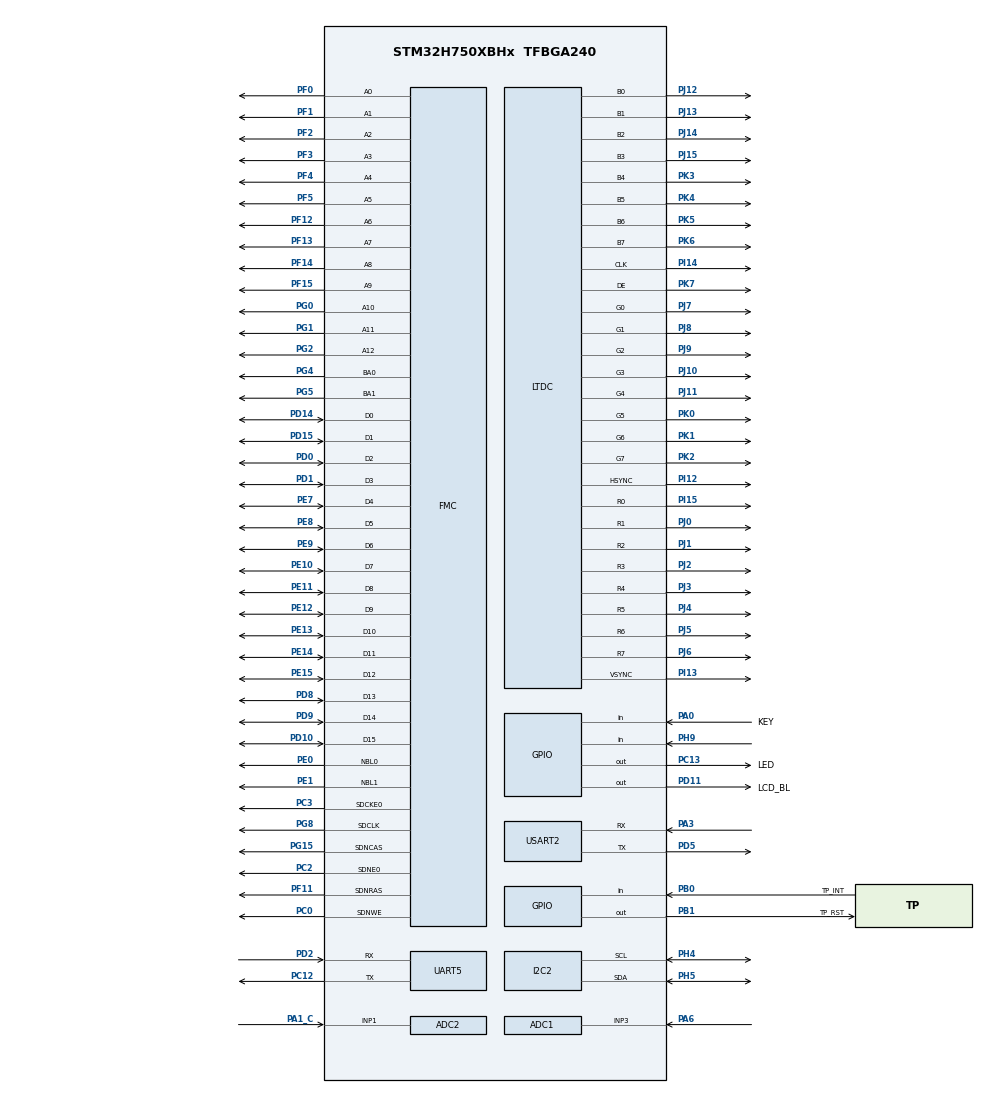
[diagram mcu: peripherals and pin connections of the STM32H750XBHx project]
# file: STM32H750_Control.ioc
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ADC1.Channel-0\#ChannelRegularConversion=ADC_CHANNEL_3
ADC1.NbrOfConversionFlag=1
ADC1.OffsetNumber-0\#ChannelRegularConversion=ADC_OFFSET_NONE
ADC1.OffsetSignedSaturation-0\#ChannelRegularConversion=DISABLE
ADC1.Rank-0\#ChannelRegularConversion=1
ADC1.SamplingTime-0\#ChannelRegularConversion=ADC_SAMPLETIME_1CYCLE_5
ADC1.master=1
ADC2.Channel-1\#ChannelRegularConversion=ADC_CHANNEL_1
ADC2.NbrOfConversionFlag=1
ADC2.OffsetNumber-1\#ChannelRegularConversion=ADC_OFFSET_NONE
ADC2.OffsetSignedSaturation-1\#ChannelRegularConversion=DISABLE
ADC2.Rank-1\#ChannelRegularConversion=1
ADC2.SamplingTime-1\#ChannelRegularConversion=ADC_SAMPLETIME_1CYCLE_5
DMA2D.ColorMode=DMA2D_OUTPUT_RGB888
FMC.CASLatency1=FMC_SDRAM_CAS_LATENCY_3
FMC.ColumnBitsNumber1=FMC_SDRAM_COLUMN_BITS_NUM_9
FMC.ExitSelfRefreshDelay1=7
FMC.LoadToActiveDelay1=2
FMC.RCDDelay1=2
FMC.RPDelay1=2
FMC.ReadPipeDelay1=FMC_SDRAM_RPIPE_DELAY_1
FMC.RowCycleDelay1=7
FMC.SDClockPeriod1=FMC_SDRAM_CLOCK_PERIOD_2
FMC.SelfRefreshTime1=4
FMC.WriteRecoveryTime1=3
FREERTOS.Tasks01=defaultTask,0,2048,StartDefaultTask,Default,NULL,Dynamic,NULL,NULL
I2C2.Timing=0x307075B1
LTDC.ActiveW=800
LTDC.Alpha_L0=255
LTDC.FBStartAdress_L0=0
LTDC.HBP=46
LTDC.HFP=40
LTDC.HSync=1
LTDC.ImageHeight_L0=480
LTDC.ImageWidth_L0=800
LTDC.Layers=0
LTDC.PixelFormat_L0=LTDC_PIXEL_FORMAT_RGB888
LTDC.VBP=23
LTDC.VFP=10
LTDC.VSync=2
LTDC.WindowX1_L0=800
LTDC.WindowY1_L0=480
Mcu.Family=STM32H7
Mcu.Name=STM32H750XBHx
Mcu.Package=TFBGA240
NVIC.DMA2D_IRQn=true\:5\:0\:false\:false\:true\:true\:true\:true
NVIC.FMC_IRQn=true\:5\:0\:false\:false\:true\:true\:true\:true
NVIC.LTDC_IRQn=true\:5\:0\:false\:false\:true\:true\:true\:true
NVIC.PriorityGroup=NVIC_PRIORITYGROUP_4
NVIC.TIM7_IRQn=true\:0\:0\:false\:false\:true\:false\:false\:true
NVIC.TimeBase=TIM7_IRQn
NVIC.TimeBaseIP=TIM7
PA0.GPIO_Label=KEY
PA0.Signal=GPIO_Input
PA1_C.Signal=ADCx_INP1
PA3.Mode=Asynchronous
PA3.Signal=USART2_RX
PA6.Signal=ADCx_INP3
PA7.Signal=ADCx_INN3
PB0.GPIO_Label=TP_INT
PB0.Signal=GPIO_Input
PB1.GPIO_Label=TP_RST
PB1.GPIO_PuPd=GPIO_PULLUP
PB1.PinState=GPIO_PIN_SET
PB1.Signal=GPIO_Output
PC0.Signal=FMC_SDNWE
PC12.Mode=Asynchronous
PC12.Signal=UART5_TX
PC13.GPIO_Label=LED
PC13.Signal=GPIO_Output
PC2.Mode=SdramChipSelect1_1
PC2.Signal=FMC_SDNE0
PC3.Mode=SdramChipSelect1_1
PC3.Signal=FMC_SDCKE0
PD0.Signal=FMC_D2_DA2
PD1.Signal=FMC_D3_DA3
PD10.Signal=FMC_D15_DA15
PD11.GPIO_Label=LCD_BL
PD11.GPIO_PuPd=GPIO_PULLUP
PD11.PinState=GPIO_PIN_SET
PD11.Signal=GPIO_Output
PD14.Signal=FMC_D0_DA0
PD15.Signal=FMC_D1_DA1
PD2.Mode=Asynchronous
PD2.Signal=UART5_RX
PD5.Mode=Asynchronous
PD5.Signal=USART2_TX
PD8.Signal=FMC_D13_DA13
PD9.Signal=FMC_D14_DA14
PE0.Signal=FMC_NBL0
PE1.Signal=FMC_NBL1
PE10.Signal=FMC_D7_DA7
PE11.Signal=FMC_D8_DA8
PE12.Signal=FMC_D9_DA9
PE13.Signal=FMC_D10_DA10
PE14.Signal=FMC_D11_DA11
PE15.Signal=FMC_D12_DA12
PE7.Signal=FMC_D4_DA4
PE8.Signal=FMC_D5_DA5
PE9.Signal=FMC_D6_DA6
PF0.Signal=FMC_A0
PF1.Signal=FMC_A1
PF11.Signal=FMC_SDNRAS
PF12.Signal=FMC_A6
PF13.Signal=FMC_A7
PF14.Signal=FMC_A8
PF15.Signal=FMC_A9
PF2.Signal=FMC_A2
PF3.Signal=FMC_A3
PF4.Signal=FMC_A4
PF5.Signal=FMC_A5
PG0.Signal=FMC_A10
PG1.Signal=FMC_A11
PG15.Signal=FMC_SDNCAS
PG2.Signal=FMC_A12
PG4.Signal=FMC_A14_BA0
PG5.Signal=FMC_A15_BA1
PG8.Signal=FMC_SDCLK
PH0-OSC_IN\ (PH0).Mode=HSE-External-Oscillator
PH0-OSC_IN\ (PH0).Signal=RCC_OSC_IN
PH1-OSC_OUT\ (PH1).Mode=HSE-External-Oscillator
PH1-OSC_OUT\ (PH1).Signal=RCC_OSC_OUT
PH4.Mode=I2C
PH4.Signal=I2C2_SCL
PH5.Mode=I2C
PH5.Signal=I2C2_SDA
PH9.GPIO_PuPd=GPIO_PULLDOWN
PH9.Signal=GPIO_Input
PI12.Mode=RGB888
PI12.Signal=LTDC_HSYNC
PI13.Mode=RGB888
PI13.Signal=LTDC_VSYNC
PI14.Mode=RGB888
PI14.Signal=LTDC_CLK
PI15.Mode=RGB888
PI15.Signal=LTDC_R0
PJ0.Mode=RGB888
PJ0.Signal=LTDC_R1
PJ1.Mode=RGB888
PJ1.Signal=LTDC_R2
PJ10.Mode=RGB888
PJ10.Signal=LTDC_G3
PJ11.Mode=RGB888
PJ11.Signal=LTDC_G4
PJ12.Mode=RGB888
PJ12.Signal=LTDC_B0
PJ13.Mode=RGB888
PJ13.Signal=LTDC_B1
PJ14.Mode=RGB888
PJ14.Signal=LTDC_B2
PJ15.Mode=RGB888
PJ15.Signal=LTDC_B3
PJ2.Mode=RGB888
PJ2.Signal=LTDC_R3
PJ3.Mode=RGB888
PJ3.Signal=LTDC_R4
PJ4.Mode=RGB888
PJ4.Signal=LTDC_R5
PJ5.Mode=RGB888
PJ5.Signal=LTDC_R6
PJ6.Mode=RGB888
PJ6.Signal=LTDC_R7
PJ7.Mode=RGB888
PJ7.Signal=LTDC_G0
PJ8.Mode=RGB888
PJ8.Signal=LTDC_G1
PJ9.Mode=RGB888
PJ9.Signal=LTDC_G2
PK0.Mode=RGB888
PK0.Signal=LTDC_G5
PK1.Mode=RGB888
PK1.Signal=LTDC_G6
PK2.Mode=RGB888
PK2.Signal=LTDC_G7
PK3.Mode=RGB888
PK3.Signal=LTDC_B4
PK4.Mode=RGB888
PK4.Signal=LTDC_B5
PK5.Mode=RGB888
PK5.Signal=LTDC_B6
PK6.Mode=RGB888
PK6.Signal=LTDC_B7
PK7.Mode=RGB888
PK7.Signal=LTDC_DE
ProjectManager.HeapSize=0x200
ProjectManager.StackSize=0x400
ProjectManager.TargetToolchain=MDK-ARM V5.27
RCC.ADCFreq_Value=75000000
RCC.APB1Freq_Value=120000000
RCC.APB2Freq_Value=120000000
RCC.APB3Freq_Value=120000000
RCC.APB4Freq_Value=120000000
RCC.CortexFreq_Value=480000000
RCC.D1PPRE=RCC_APB3_DIV2
RCC.D2PPRE1=RCC_APB1_DIV2
RCC.D2PPRE2=RCC_APB2_DIV2
RCC.D3PPRE=RCC_APB4_DIV2
RCC.DIVM1=5
RCC.DIVM2=2
RCC.DIVM3=3
RCC.DIVN1=192
RCC.DIVN2=12
RCC.DIVN3=51
RCC.DIVR3=25
RCC.HCLKFreq_Value=240000000
RCC.HPRE=RCC_HCLK_DIV2
RCC.HSE_VALUE=25000000
RCC.PLL3FRACN=0
RCC.PLLFRACN=0
RCC.PLLSourceVirtual=RCC_PLLSOURCE_HSE
RCC.SYSCLKFreq_VALUE=480000000
RCC.SYSCLKSource=RCC_SYSCLKSOURCE_PLLCLK
RCC.USBFreq_Value=480000000
SH.ADCx_INN3.0=ADC2_INN3
SH.ADCx_INP1.0=ADC2_INP1,IN1-Single-Ended
SH.ADCx_INP3.0=ADC1_INP3,IN3-Single-Ended
SH.FMC_A0.0=FMC_A0,13b-sda1
SH.FMC_A1.0=FMC_A1,13b-sda1
SH.FMC_A10.0=FMC_A10,13b-sda1
SH.FMC_A11.0=FMC_A11,13b-sda1
SH.FMC_A12.0=FMC_A12,13b-sda1
SH.FMC_A14_BA0.0=FMC_BA0,FourSdramBanks1
SH.FMC_A15_BA1.0=FMC_BA1,FourSdramBanks1
SH.FMC_A2.0=FMC_A2,13b-sda1
SH.FMC_A3.0=FMC_A3,13b-sda1
SH.FMC_A4.0=FMC_A4,13b-sda1
SH.FMC_A5.0=FMC_A5,13b-sda1
SH.FMC_A6.0=FMC_A6,13b-sda1
SH.FMC_A7.0=FMC_A7,13b-sda1
SH.FMC_A8.0=FMC_A8,13b-sda1
SH.FMC_A9.0=FMC_A9,13b-sda1
SH.FMC_D0_DA0.0=FMC_D0,sd-16b-d1
SH.FMC_D10_DA10.0=FMC_D10,sd-16b-d1
SH.FMC_D11_DA11.0=FMC_D11,sd-16b-d1
SH.FMC_D12_DA12.0=FMC_D12,sd-16b-d1
SH.FMC_D13_DA13.0=FMC_D13,sd-16b-d1
SH.FMC_D14_DA14.0=FMC_D14,sd-16b-d1
SH.FMC_D15_DA15.0=FMC_D15,sd-16b-d1
SH.FMC_D1_DA1.0=FMC_D1,sd-16b-d1
SH.FMC_D2_DA2.0=FMC_D2,sd-16b-d1
SH.FMC_D3_DA3.0=FMC_D3,sd-16b-d1
SH.FMC_D4_DA4.0=FMC_D4,sd-16b-d1
SH.FMC_D5_DA5.0=FMC_D5,sd-16b-d1
SH.FMC_D6_DA6.0=FMC_D6,sd-16b-d1
SH.FMC_D7_DA7.0=FMC_D7,sd-16b-d1
SH.FMC_D8_DA8.0=FMC_D8,sd-16b-d1
SH.FMC_D9_DA9.0=FMC_D9,sd-16b-d1
SH.FMC_NBL0.0=FMC_NBL0,Sd2ByteEnable1
SH.FMC_NBL1.0=FMC_NBL1,Sd2ByteEnable1
SH.FMC_SDCLK.0=FMC_SDCLK,13b-sda1
SH.FMC_SDNCAS.0=FMC_SDNCAS,13b-sda1
SH.FMC_SDNRAS.0=FMC_SDNRAS,13b-sda1
SH.FMC_SDNWE.0=FMC_SDNWE,13b-sda1
STMicroelectronics.X-CUBE-TOUCHGFX.4.17.0.ApplicationCcGraphicsJjApplication=TouchGFXOoGenerator
STMicroelectronics.X-CUBE-TOUCHGFX.4.17.0.tgfx_address1=0xC0000000
STMicroelectronics.X-CUBE-TOUCHGFX.4.17.0.tgfx_address2=0xC0119400
STMicroelectronics.X-CUBE-TOUCHGFX.4.17.0.tgfx_buffering_strategy=Double
STMicroelectronics.X-CUBE-TOUCHGFX.4.17.0.tgfx_display_interface=disp_ltdc
STMicroelectronics.X-CUBE-TOUCHGFX.4.17.0.tgfx_hardware_accelerator=dma_2d
STMicroelectronics.X-CUBE-TOUCHGFX.4.17.0.tgfx_location=By Address
STMicroelectronics.X-CUBE-TOUCHGFX.4.17.0.tgfx_vsync=vsync_ltdc
USART2.VirtualMode-Asynchronous=VM_ASYNC
VP_CRC_VS_CRC.Mode=CRC_Activate
VP_DMA2D_VS_DMA2D.Mode=DMA2D_Activate
VP_FREERTOS_VS_CMSIS_V1.Mode=CMSIS_V1
VP_STMicroelectronics.X-CUBE-TOUCHGFX_VS_GraphicsJjApplication_4.17.0.Mode=GraphicsJjApplication
VP_SYS_VS_tim7.Mode=TIM7
board=custom

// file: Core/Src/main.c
/* USER CODE BEGIN Header */
/**
  ******************************************************************************
  * @file           : main.c
  * @brief          : Main program body
  ******************************************************************************
  * @attention
  *
  * <h2><center>&copy; Copyright (c) 2020 STMicroelectronics.
  * All rights reserved.</center></h2>
  *
  * This software component is licensed by ST under Ultimate Liberty license
  * SLA0044, the "License"; You may not use this file except in compliance with
  * the License. You may obtain a copy of the License at:
  *                             www.st.com/SLA0044
  *
  ******************************************************************************
  */
/* USER CODE END Header */
#include "main.h"
#include "cmsis_os.h"
#include "app_touchgfx.h"

/* USER CODE BEGIN Includes */
#include "bsp_sdram.h"
#include "stdio.h"
/* USER CODE END Includes */

ADC_HandleTypeDef hadc1;
ADC_HandleTypeDef hadc2;

CRC_HandleTypeDef hcrc;

DMA2D_HandleTypeDef hdma2d;

I2C_HandleTypeDef hi2c2;

LTDC_HandleTypeDef hltdc;

UART_HandleTypeDef huart5;
UART_HandleTypeDef huart2;

SDRAM_HandleTypeDef hsdram1;

osThreadId defaultTaskHandle;

void SystemClock_Config(void);
static void MX_GPIO_Init(void);
static void MX_DMA2D_Init(void);
static void MX_FMC_Init(void);
static void MX_I2C2_Init(void);
static void MX_LTDC_Init(void);
static void MX_CRC_Init(void);
static void MX_UART5_Init(void);
static void MX_USART2_UART_Init(void);
static void MX_ADC2_Init(void);
static void MX_ADC1_Init(void);
void StartDefaultTask(void const * argument);

/* USER CODE BEGIN PFP */
int32_t adc_value;
int32_t i, j;
int32_t filter_temp, filter_sum = 0;
const int FILTER_N = 20;
int32_t filter_buf[FILTER_N];
/* USER CODE END PFP */

/* USER CODE BEGIN 0 */
#ifdef __GNUC__
#define PUTCHAR_PROTOTYPE int __io_putchar(int ch)
#else
#define PUTCHAR_PROTOTYPE int fputc(int ch, FILE *f)
#endif
PUTCHAR_PROTOTYPE
{
    HAL_UART_Transmit(&huart2 , (uint8_t *)&ch, 1, 0xFFFF);
    return ch;
}
/* USER CODE END 0 */

int main(void)
{

  /* MCU Configuration--------------------------------------------------------*/

  /* Reset of all peripherals, Initializes the Flash interface and the Systick. */
  HAL_Init();

  /* Configure the system clock */
  SystemClock_Config();

  /* Initialize all configured peripherals */
  MX_GPIO_Init();
  MX_DMA2D_Init();
  MX_FMC_Init();
  MX_I2C2_Init();
  MX_LTDC_Init();
  MX_CRC_Init();
  MX_UART5_Init();
  MX_USART2_UART_Init();
  MX_ADC2_Init();
  MX_ADC1_Init();
  MX_TouchGFX_Init();
  /* USER CODE BEGIN 2 */
	SDRAM_Init();
  /* USER CODE END 2 */

  /* Create the thread(s) */
  /* definition and creation of defaultTask */
  osThreadDef(defaultTask, StartDefaultTask, osPriorityNormal, 0, 2048);
  defaultTaskHandle = osThreadCreate(osThread(defaultTask), NULL);

  /* Start scheduler */
  osKernelStart();

  /* We should never get here as control is now taken by the scheduler */
  /* Infinite loop */
  /* USER CODE BEGIN WHILE */
  while (1)
  {	/*
		HAL_ADC_Start(&hadc2);
		HAL_ADC_PollForConversion(&hadc2,10);
		adc_value = HAL_ADC_GetValue(&hadc2);
		printf("ADC1_IN1 ADC value: %d\r\n",adc_value);
		adc_value = adc_value*(3.3/4096);
		printf("ADC1_IN1 VOL value: %.2fV\r\n",(double)adc_value);

		HAL_GPIO_TogglePin(GPIOA,GPIO_PIN_1);
		HAL_Delay(10);
		*/

    /* USER CODE END WHILE */

  }
}

void SystemClock_Config(void)
{
  RCC_OscInitTypeDef RCC_OscInitStruct = {0};
  RCC_ClkInitTypeDef RCC_ClkInitStruct = {0};
  RCC_PeriphCLKInitTypeDef PeriphClkInitStruct = {0};

  /** Supply configuration update enable
  */
  HAL_PWREx_ConfigSupply(PWR_LDO_SUPPLY);
  /** Configure the main internal regulator output voltage
  */
  __HAL_PWR_VOLTAGESCALING_CONFIG(PWR_REGULATOR_VOLTAGE_SCALE0);

  while(!__HAL_PWR_GET_FLAG(PWR_FLAG_VOSRDY)) {}
  /** Macro to configure the PLL clock source
  */
  __HAL_RCC_PLL_PLLSOURCE_CONFIG(RCC_PLLSOURCE_HSE);
  /** Initializes the RCC Oscillators according to the specified parameters
  * in the RCC_OscInitTypeDef structure.
  */
  RCC_OscInitStruct.OscillatorType = RCC_OSCILLATORTYPE_HSE;
  RCC_OscInitStruct.HSEState = RCC_HSE_ON;
  RCC_OscInitStruct.PLL.PLLState = RCC_PLL_ON;
  RCC_OscInitStruct.PLL.PLLSource = RCC_PLLSOURCE_HSE;
  RCC_OscInitStruct.PLL.PLLM = 5;
  RCC_OscInitStruct.PLL.PLLN = 192;
  RCC_OscInitStruct.PLL.PLLP = 2;
  RCC_OscInitStruct.PLL.PLLQ = 2;
  RCC_OscInitStruct.PLL.PLLR = 2;
  RCC_OscInitStruct.PLL.PLLRGE = RCC_PLL1VCIRANGE_2;
  RCC_OscInitStruct.PLL.PLLVCOSEL = RCC_PLL1VCOWIDE;
  RCC_OscInitStruct.PLL.PLLFRACN = 0;
  if (HAL_RCC_OscConfig(&RCC_OscInitStruct) != HAL_OK)
  {
    Error_Handler();
  }
  /** Initializes the CPU, AHB and APB buses clocks
  */
  RCC_ClkInitStruct.ClockType = RCC_CLOCKTYPE_HCLK|RCC_CLOCKTYPE_SYSCLK
                              |RCC_CLOCKTYPE_PCLK1|RCC_CLOCKTYPE_PCLK2
                              |RCC_CLOCKTYPE_D3PCLK1|RCC_CLOCKTYPE_D1PCLK1;
  RCC_ClkInitStruct.SYSCLKSource = RCC_SYSCLKSOURCE_PLLCLK;
  RCC_ClkInitStruct.SYSCLKDivider = RCC_SYSCLK_DIV1;
  RCC_ClkInitStruct.AHBCLKDivider = RCC_HCLK_DIV2;
  RCC_ClkInitStruct.APB3CLKDivider = RCC_APB3_DIV2;
  RCC_ClkInitStruct.APB1CLKDivider = RCC_APB1_DIV2;
  RCC_ClkInitStruct.APB2CLKDivider = RCC_APB2_DIV2;
  RCC_ClkInitStruct.APB4CLKDivider = RCC_APB4_DIV2;

  if (HAL_RCC_ClockConfig(&RCC_ClkInitStruct, FLASH_LATENCY_4) != HAL_OK)
  {
    Error_Handler();
  }
  PeriphClkInitStruct.PeriphClockSelection = RCC_PERIPHCLK_LTDC|RCC_PERIPHCLK_USART2
                              |RCC_PERIPHCLK_UART5|RCC_PERIPHCLK_I2C2
                              |RCC_PERIPHCLK_ADC|RCC_PERIPHCLK_FMC;
  PeriphClkInitStruct.PLL2.PLL2M = 2;
  PeriphClkInitStruct.PLL2.PLL2N = 12;
  PeriphClkInitStruct.PLL2.PLL2P = 2;
  PeriphClkInitStruct.PLL2.PLL2Q = 2;
  PeriphClkInitStruct.PLL2.PLL2R = 2;
  PeriphClkInitStruct.PLL2.PLL2RGE = RCC_PLL2VCIRANGE_3;
  PeriphClkInitStruct.PLL2.PLL2VCOSEL = RCC_PLL2VCOMEDIUM;
  PeriphClkInitStruct.PLL2.PLL2FRACN = 0;
  PeriphClkInitStruct.PLL3.PLL3M = 3;
  PeriphClkInitStruct.PLL3.PLL3N = 51;
  PeriphClkInitStruct.PLL3.PLL3P = 2;
  PeriphClkInitStruct.PLL3.PLL3Q = 2;
  PeriphClkInitStruct.PLL3.PLL3R = 25;
  PeriphClkInitStruct.PLL3.PLL3RGE = RCC_PLL3VCIRANGE_3;
  PeriphClkInitStruct.PLL3.PLL3VCOSEL = RCC_PLL3VCOWIDE;
  PeriphClkInitStruct.PLL3.PLL3FRACN = 0;
  PeriphClkInitStruct.FmcClockSelection = RCC_FMCCLKSOURCE_D1HCLK;
  PeriphClkInitStruct.Usart234578ClockSelection = RCC_USART234578CLKSOURCE_D2PCLK1;
  PeriphClkInitStruct.I2c123ClockSelection = RCC_I2C123CLKSOURCE_D2PCLK1;
  PeriphClkInitStruct.AdcClockSelection = RCC_ADCCLKSOURCE_PLL2;
  if (HAL_RCCEx_PeriphCLKConfig(&PeriphClkInitStruct) != HAL_OK)
  {
    Error_Handler();
  }
}

static void MX_ADC1_Init(void)
{

  ADC_MultiModeTypeDef multimode = {0};
  ADC_ChannelConfTypeDef sConfig = {0};

  /** Common config
  */
  hadc1.Instance = ADC1;
  hadc1.Init.ClockPrescaler = ADC_CLOCK_ASYNC_DIV1;
  hadc1.Init.Resolution = ADC_RESOLUTION_16B;
  hadc1.Init.ScanConvMode = ADC_SCAN_DISABLE;
  hadc1.Init.EOCSelection = ADC_EOC_SINGLE_CONV;
  hadc1.Init.LowPowerAutoWait = DISABLE;
  hadc1.Init.ContinuousConvMode = DISABLE;
  hadc1.Init.NbrOfConversion = 1;
  hadc1.Init.DiscontinuousConvMode = DISABLE;
  hadc1.Init.ExternalTrigConv = ADC_SOFTWARE_START;
  hadc1.Init.ExternalTrigConvEdge = ADC_EXTERNALTRIGCONVEDGE_NONE;
  hadc1.Init.ConversionDataManagement = ADC_CONVERSIONDATA_DR;
  hadc1.Init.Overrun = ADC_OVR_DATA_PRESERVED;
  hadc1.Init.LeftBitShift = ADC_LEFTBITSHIFT_NONE;
  hadc1.Init.OversamplingMode = DISABLE;
  if (HAL_ADC_Init(&hadc1) != HAL_OK)
  {
    Error_Handler();
  }
  /** Configure the ADC multi-mode
  */
  multimode.Mode = ADC_MODE_INDEPENDENT;
  if (HAL_ADCEx_MultiModeConfigChannel(&hadc1, &multimode) != HAL_OK)
  {
    Error_Handler();
  }
  /** Configure Regular Channel
  */
  sConfig.Channel = ADC_CHANNEL_3;
  sConfig.Rank = ADC_REGULAR_RANK_1;
  sConfig.SamplingTime = ADC_SAMPLETIME_1CYCLE_5;
  sConfig.SingleDiff = ADC_SINGLE_ENDED;
  sConfig.OffsetNumber = ADC_OFFSET_NONE;
  sConfig.Offset = 0;
  sConfig.OffsetSignedSaturation = DISABLE;
  if (HAL_ADC_ConfigChannel(&hadc1, &sConfig) != HAL_OK)
  {
    Error_Handler();
  }

}

static void MX_ADC2_Init(void)
{

  ADC_ChannelConfTypeDef sConfig = {0};

  /** Common config
  */
  hadc2.Instance = ADC2;
  hadc2.Init.ClockPrescaler = ADC_CLOCK_ASYNC_DIV1;
  hadc2.Init.Resolution = ADC_RESOLUTION_16B;
  hadc2.Init.ScanConvMode = ADC_SCAN_DISABLE;
  hadc2.Init.EOCSelection = ADC_EOC_SINGLE_CONV;
  hadc2.Init.LowPowerAutoWait = DISABLE;
  hadc2.Init.ContinuousConvMode = DISABLE;
  hadc2.Init.NbrOfConversion = 1;
  hadc2.Init.DiscontinuousConvMode = DISABLE;
  hadc2.Init.ExternalTrigConv = ADC_SOFTWARE_START;
  hadc2.Init.ExternalTrigConvEdge = ADC_EXTERNALTRIGCONVEDGE_NONE;
  hadc2.Init.ConversionDataManagement = ADC_CONVERSIONDATA_DR;
  hadc2.Init.Overrun = ADC_OVR_DATA_PRESERVED;
  hadc2.Init.LeftBitShift = ADC_LEFTBITSHIFT_NONE;
  hadc2.Init.OversamplingMode = DISABLE;
  if (HAL_ADC_Init(&hadc2) != HAL_OK)
  {
    Error_Handler();
  }
  /** Configure Regular Channel
  */
  sConfig.Channel = ADC_CHANNEL_1;
  sConfig.Rank = ADC_REGULAR_RANK_1;
  sConfig.SamplingTime = ADC_SAMPLETIME_1CYCLE_5;
  sConfig.SingleDiff = ADC_SINGLE_ENDED;
  sConfig.OffsetNumber = ADC_OFFSET_NONE;
  sConfig.Offset = 0;
  sConfig.OffsetSignedSaturation = DISABLE;
  if (HAL_ADC_ConfigChannel(&hadc2, &sConfig) != HAL_OK)
  {
    Error_Handler();
  }

}

static void MX_CRC_Init(void)
{

  hcrc.Instance = CRC;
  hcrc.Init.DefaultPolynomialUse = DEFAULT_POLYNOMIAL_ENABLE;
  hcrc.Init.DefaultInitValueUse = DEFAULT_INIT_VALUE_ENABLE;
  hcrc.Init.InputDataInversionMode = CRC_INPUTDATA_INVERSION_NONE;
  hcrc.Init.OutputDataInversionMode = CRC_OUTPUTDATA_INVERSION_DISABLE;
  hcrc.InputDataFormat = CRC_INPUTDATA_FORMAT_BYTES;
  if (HAL_CRC_Init(&hcrc) != HAL_OK)
  {
    Error_Handler();
  }

}

static void MX_DMA2D_Init(void)
{

  hdma2d.Instance = DMA2D;
  hdma2d.Init.Mode = DMA2D_M2M;
  hdma2d.Init.ColorMode = DMA2D_OUTPUT_RGB888;
  hdma2d.Init.OutputOffset = 0;
  hdma2d.Init.BytesSwap = DMA2D_BYTES_REGULAR;
  hdma2d.Init.LineOffsetMode = DMA2D_LOM_PIXELS;
  hdma2d.LayerCfg[1].InputOffset = 0;
  hdma2d.LayerCfg[1].InputColorMode = DMA2D_INPUT_RGB888;
  hdma2d.LayerCfg[1].AlphaMode = DMA2D_NO_MODIF_ALPHA;
  hdma2d.LayerCfg[1].InputAlpha = 0;
  hdma2d.LayerCfg[1].AlphaInverted = DMA2D_REGULAR_ALPHA;
  hdma2d.LayerCfg[1].RedBlueSwap = DMA2D_RB_REGULAR;
  hdma2d.LayerCfg[1].ChromaSubSampling = DMA2D_NO_CSS;
  if (HAL_DMA2D_Init(&hdma2d) != HAL_OK)
  {
    Error_Handler();
  }
  if (HAL_DMA2D_ConfigLayer(&hdma2d, 1) != HAL_OK)
  {
    Error_Handler();
  }

}

static void MX_I2C2_Init(void)
{

  hi2c2.Instance = I2C2;
  hi2c2.Init.Timing = 0x307075B1;
  hi2c2.Init.OwnAddress1 = 0;
  hi2c2.Init.AddressingMode = I2C_ADDRESSINGMODE_7BIT;
  hi2c2.Init.DualAddressMode = I2C_DUALADDRESS_DISABLE;
  hi2c2.Init.OwnAddress2 = 0;
  hi2c2.Init.OwnAddress2Masks = I2C_OA2_NOMASK;
  hi2c2.Init.GeneralCallMode = I2C_GENERALCALL_DISABLE;
  hi2c2.Init.NoStretchMode = I2C_NOSTRETCH_DISABLE;
  if (HAL_I2C_Init(&hi2c2) != HAL_OK)
  {
    Error_Handler();
  }
  /** Configure Analogue filter
  */
  if (HAL_I2CEx_ConfigAnalogFilter(&hi2c2, I2C_ANALOGFILTER_ENABLE) != HAL_OK)
  {
    Error_Handler();
  }
  /** Configure Digital filter
  */
  if (HAL_I2CEx_ConfigDigitalFilter(&hi2c2, 0) != HAL_OK)
  {
    Error_Handler();
  }

}

static void MX_LTDC_Init(void)
{

  LTDC_LayerCfgTypeDef pLayerCfg = {0};

  hltdc.Instance = LTDC;
  hltdc.Init.HSPolarity = LTDC_HSPOLARITY_AL;
  hltdc.Init.VSPolarity = LTDC_VSPOLARITY_AL;
  hltdc.Init.DEPolarity = LTDC_DEPOLARITY_AL;
  hltdc.Init.PCPolarity = LTDC_PCPOLARITY_IPC;
  hltdc.Init.HorizontalSync = 0;
  hltdc.Init.VerticalSync = 1;
  hltdc.Init.AccumulatedHBP = 46;
  hltdc.Init.AccumulatedVBP = 24;
  hltdc.Init.AccumulatedActiveW = 846;
  hltdc.Init.AccumulatedActiveH = 504;
  hltdc.Init.TotalWidth = 886;
  hltdc.Init.TotalHeigh = 514;
  hltdc.Init.Backcolor.Blue = 0;
  hltdc.Init.Backcolor.Green = 0;
  hltdc.Init.Backcolor.Red = 0;
  if (HAL_LTDC_Init(&hltdc) != HAL_OK)
  {
    Error_Handler();
  }
  pLayerCfg.WindowX0 = 0;
  pLayerCfg.WindowX1 = 800;
  pLayerCfg.WindowY0 = 0;
  pLayerCfg.WindowY1 = 480;
  pLayerCfg.PixelFormat = LTDC_PIXEL_FORMAT_RGB888;
  pLayerCfg.Alpha = 255;
  pLayerCfg.Alpha0 = 0;
  pLayerCfg.BlendingFactor1 = LTDC_BLENDING_FACTOR1_CA;
  pLayerCfg.BlendingFactor2 = LTDC_BLENDING_FACTOR2_CA;
  pLayerCfg.FBStartAdress = 0;
  pLayerCfg.ImageWidth = 800;
  pLayerCfg.ImageHeight = 480;
  pLayerCfg.Backcolor.Blue = 0;
  pLayerCfg.Backcolor.Green = 0;
  pLayerCfg.Backcolor.Red = 0;
  if (HAL_LTDC_ConfigLayer(&hltdc, &pLayerCfg, 0) != HAL_OK)
  {
    Error_Handler();
  }

}

static void MX_UART5_Init(void)
{

  huart5.Instance = UART5;
  huart5.Init.BaudRate = 115200;
  huart5.Init.WordLength = UART_WORDLENGTH_8B;
  huart5.Init.StopBits = UART_STOPBITS_1;
  huart5.Init.Parity = UART_PARITY_NONE;
  huart5.Init.Mode = UART_MODE_TX_RX;
  huart5.Init.HwFlowCtl = UART_HWCONTROL_NONE;
  huart5.Init.OverSampling = UART_OVERSAMPLING_16;
  huart5.Init.OneBitSampling = UART_ONE_BIT_SAMPLE_DISABLE;
  huart5.Init.ClockPrescaler = UART_PRESCALER_DIV1;
  huart5.AdvancedInit.AdvFeatureInit = UART_ADVFEATURE_NO_INIT;
  if (HAL_UART_Init(&huart5) != HAL_OK)
  {
    Error_Handler();
  }
  if (HAL_UARTEx_SetTxFifoThreshold(&huart5, UART_TXFIFO_THRESHOLD_1_8) != HAL_OK)
  {
    Error_Handler();
  }
  if (HAL_UARTEx_SetRxFifoThreshold(&huart5, UART_RXFIFO_THRESHOLD_1_8) != HAL_OK)
  {
    Error_Handler();
  }
  if (HAL_UARTEx_DisableFifoMode(&huart5) != HAL_OK)
  {
    Error_Handler();
  }

}

static void MX_USART2_UART_Init(void)
{

  huart2.Instance = USART2;
  huart2.Init.BaudRate = 115200;
  huart2.Init.WordLength = UART_WORDLENGTH_8B;
  huart2.Init.StopBits = UART_STOPBITS_1;
  huart2.Init.Parity = UART_PARITY_NONE;
  huart2.Init.Mode = UART_MODE_TX_RX;
  huart2.Init.HwFlowCtl = UART_HWCONTROL_NONE;
  huart2.Init.OverSampling = UART_OVERSAMPLING_16;
  huart2.Init.OneBitSampling = UART_ONE_BIT_SAMPLE_DISABLE;
  huart2.Init.ClockPrescaler = UART_PRESCALER_DIV1;
  huart2.AdvancedInit.AdvFeatureInit = UART_ADVFEATURE_NO_INIT;
  if (HAL_UART_Init(&huart2) != HAL_OK)
  {
    Error_Handler();
  }
  if (HAL_UARTEx_SetTxFifoThreshold(&huart2, UART_TXFIFO_THRESHOLD_1_8) != HAL_OK)
  {
    Error_Handler();
  }
  if (HAL_UARTEx_SetRxFifoThreshold(&huart2, UART_RXFIFO_THRESHOLD_1_8) != HAL_OK)
  {
    Error_Handler();
  }
  if (HAL_UARTEx_DisableFifoMode(&huart2) != HAL_OK)
  {
    Error_Handler();
  }

}

/* FMC initialization function */
static void MX_FMC_Init(void)
{

  FMC_SDRAM_TimingTypeDef SdramTiming = {0};

  /** Perform the SDRAM1 memory initialization sequence
  */
  hsdram1.Instance = FMC_SDRAM_DEVICE;
  /* hsdram1.Init */
  hsdram1.Init.SDBank = FMC_SDRAM_BANK1;
  hsdram1.Init.ColumnBitsNumber = FMC_SDRAM_COLUMN_BITS_NUM_9;
  hsdram1.Init.RowBitsNumber = FMC_SDRAM_ROW_BITS_NUM_13;
  hsdram1.Init.MemoryDataWidth = FMC_SDRAM_MEM_BUS_WIDTH_16;
  hsdram1.Init.InternalBankNumber = FMC_SDRAM_INTERN_BANKS_NUM_4;
  hsdram1.Init.CASLatency = FMC_SDRAM_CAS_LATENCY_3;
  hsdram1.Init.WriteProtection = FMC_SDRAM_WRITE_PROTECTION_DISABLE;
  hsdram1.Init.SDClockPeriod = FMC_SDRAM_CLOCK_PERIOD_2;
  hsdram1.Init.ReadBurst = FMC_SDRAM_RBURST_DISABLE;
  hsdram1.Init.ReadPipeDelay = FMC_SDRAM_RPIPE_DELAY_1;
  /* SdramTiming */
  SdramTiming.LoadToActiveDelay = 2;
  SdramTiming.ExitSelfRefreshDelay = 7;
  SdramTiming.SelfRefreshTime = 4;
  SdramTiming.RowCycleDelay = 7;
  SdramTiming.WriteRecoveryTime = 3;
  SdramTiming.RPDelay = 2;
  SdramTiming.RCDDelay = 2;

  if (HAL_SDRAM_Init(&hsdram1, &SdramTiming) != HAL_OK)
  {
    Error_Handler( );
  }

}

static void MX_GPIO_Init(void)
{
  GPIO_InitTypeDef GPIO_InitStruct = {0};

  /* GPIO Ports Clock Enable */
  __HAL_RCC_GPIOK_CLK_ENABLE();
  __HAL_RCC_GPIOD_CLK_ENABLE();
  __HAL_RCC_GPIOE_CLK_ENABLE();
  __HAL_RCC_GPIOJ_CLK_ENABLE();
  __HAL_RCC_GPIOC_CLK_ENABLE();
  __HAL_RCC_GPIOG_CLK_ENABLE();
  __HAL_RCC_GPIOF_CLK_ENABLE();
  __HAL_RCC_GPIOI_CLK_ENABLE();
  __HAL_RCC_GPIOH_CLK_ENABLE();
  __HAL_RCC_GPIOA_CLK_ENABLE();
  __HAL_RCC_GPIOB_CLK_ENABLE();

  /*Configure GPIO pin Output Level */
  HAL_GPIO_WritePin(LED_GPIO_Port, LED_Pin, GPIO_PIN_RESET);

  /*Configure GPIO pin Output Level */
  HAL_GPIO_WritePin(LCD_BL_GPIO_Port, LCD_BL_Pin, GPIO_PIN_SET);

  /*Configure GPIO pin Output Level */
  HAL_GPIO_WritePin(TP_RST_GPIO_Port, TP_RST_Pin, GPIO_PIN_SET);

  /*Configure GPIO pin : LED_Pin */
  GPIO_InitStruct.Pin = LED_Pin;
  GPIO_InitStruct.Mode = GPIO_MODE_OUTPUT_PP;
  GPIO_InitStruct.Pull = GPIO_NOPULL;
  GPIO_InitStruct.Speed = GPIO_SPEED_FREQ_LOW;
  HAL_GPIO_Init(LED_GPIO_Port, &GPIO_InitStruct);

  /*Configure GPIO pin : KEY_Pin */
  GPIO_InitStruct.Pin = KEY_Pin;
  GPIO_InitStruct.Mode = GPIO_MODE_INPUT;
  GPIO_InitStruct.Pull = GPIO_NOPULL;
  HAL_GPIO_Init(KEY_GPIO_Port, &GPIO_InitStruct);

  /*Configure GPIO pin : PH9 */
  GPIO_InitStruct.Pin = GPIO_PIN_9;
  GPIO_InitStruct.Mode = GPIO_MODE_INPUT;
  GPIO_InitStruct.Pull = GPIO_PULLDOWN;
  HAL_GPIO_Init(GPIOH, &GPIO_InitStruct);

  /*Configure GPIO pin : LCD_BL_Pin */
  GPIO_InitStruct.Pin = LCD_BL_Pin;
  GPIO_InitStruct.Mode = GPIO_MODE_OUTPUT_PP;
  GPIO_InitStruct.Pull = GPIO_PULLUP;
  GPIO_InitStruct.Speed = GPIO_SPEED_FREQ_LOW;
  HAL_GPIO_Init(LCD_BL_GPIO_Port, &GPIO_InitStruct);

  /*Configure GPIO pin : TP_RST_Pin */
  GPIO_InitStruct.Pin = TP_RST_Pin;
  GPIO_InitStruct.Mode = GPIO_MODE_OUTPUT_PP;
  GPIO_InitStruct.Pull = GPIO_PULLUP;
  GPIO_InitStruct.Speed = GPIO_SPEED_FREQ_LOW;
  HAL_GPIO_Init(TP_RST_GPIO_Port, &GPIO_InitStruct);

  /*Configure GPIO pin : TP_INT_Pin */
  GPIO_InitStruct.Pin = TP_INT_Pin;
  GPIO_InitStruct.Mode = GPIO_MODE_INPUT;
  GPIO_InitStruct.Pull = GPIO_NOPULL;
  HAL_GPIO_Init(TP_INT_GPIO_Port, &GPIO_InitStruct);

}

void StartDefaultTask(void const * argument)
{
  /* USER CODE BEGIN 5 */
  /* Infinite loop */
	MX_TouchGFX_Process();
  for(;;)
  {
    osDelay(1);
  }
  /* USER CODE END 5 */
}

 /**
  * @brief  Period elapsed callback in non blocking mode
  * @note   This function is called  when TIM7 interrupt took place, inside
  * HAL_TIM_IRQHandler(). It makes a direct call to HAL_IncTick() to increment
  * a global variable "uwTick" used as application time base.
  * @param  htim : TIM handle
  * @retval None
  */
void HAL_TIM_PeriodElapsedCallback(TIM_HandleTypeDef *htim)
{
  if (htim->Instance == TIM7) {
    HAL_IncTick();
  }
}

void Error_Handler(void)
{
  __disable_irq();
  while (1)
  {
  }
}

/************************ (C) COPYRIGHT STMicroelectronics *****END OF FILE****/
